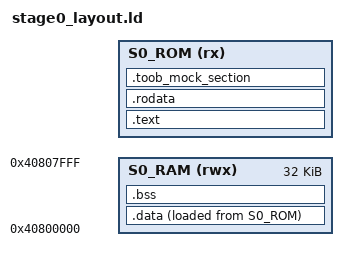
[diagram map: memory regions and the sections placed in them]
/* AUTO-GENERATED BY TOOB MANIFEST COMPILER */
/* Valid Stage 0 Layout */
ENTRY(main)

INCLUDE generated_memory.ld

MEMORY {
    S0_RAM (rwx) : ORIGIN = 0x40800000, LENGTH = 0x8000
    S0_ROM (rx)  : ORIGIN = __S0_BUDGET_START, LENGTH = __S0_BUDGET_SIZE
}

SECTIONS {
    .text : {
        KEEP(*(.text.main))
        *(.text .text.*)
    } > S0_ROM

    .rodata : {
        *(.rodata .rodata.*)
        *(.srodata .srodata.*)
    } > S0_ROM

    .data : {
        *(.data .data.*)
        *(.sdata .sdata.*)
    } > S0_RAM AT > S0_ROM

    .bss (NOLOAD) : {
        *(.bss .bss.*)
        *(.sbss .sbss.*)
        *(COMMON)
    } > S0_RAM

    .toob_mock_section : {
        KEEP(*(.toob_mock_section))
    } > S0_ROM
}
